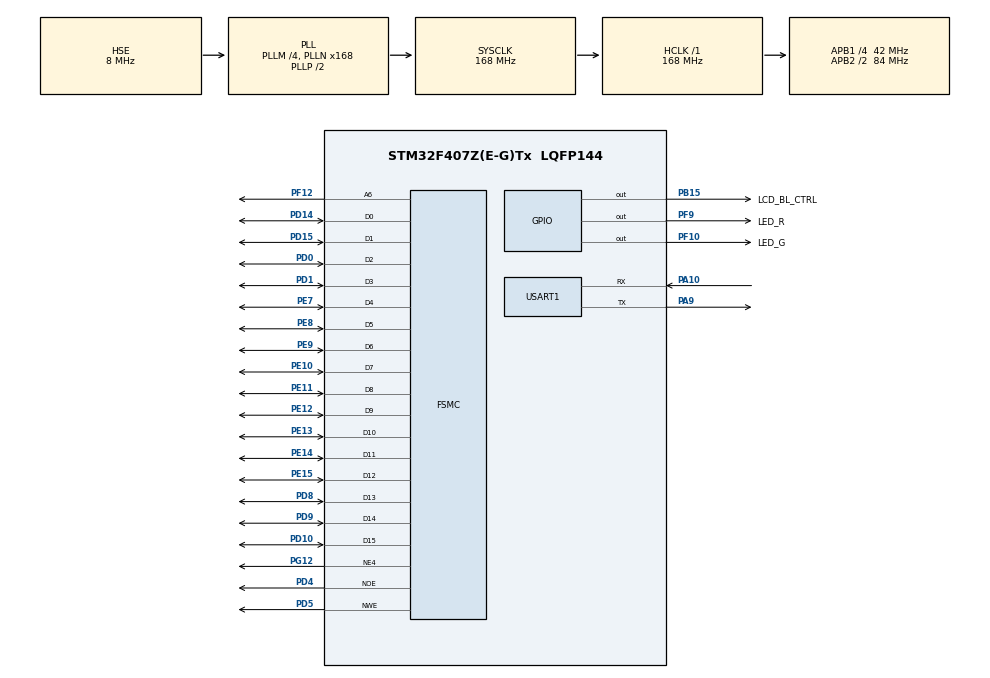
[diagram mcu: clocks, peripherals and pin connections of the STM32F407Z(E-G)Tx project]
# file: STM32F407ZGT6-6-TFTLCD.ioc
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FSMC.BusTurnAroundDuration4=0
FSMC.DataSetupTime4=60
FSMC.ExtendedAddressSetupTime4=3
FSMC.ExtendedBusTurnAroundDuration4=0
FSMC.ExtendedDataSetupTime4=2
FSMC.ExtendedMode4=FSMC_EXTENDED_MODE_ENABLE
Mcu.Family=STM32F4
Mcu.Name=STM32F407Z(E-G)Tx
Mcu.Package=LQFP144
NVIC.PriorityGroup=NVIC_PRIORITYGROUP_2
NVIC.USART1_IRQn=true\:2\:2\:true\:false\:true\:true\:true
PA10.GPIO_PuPd=GPIO_PULLUP
PA10.GPIO_Speed=GPIO_SPEED_FREQ_HIGH
PA10.Mode=Asynchronous
PA10.Signal=USART1_RX
PA13.Mode=Serial_Wire
PA13.Signal=SYS_JTMS-SWDIO
PA14.Mode=Serial_Wire
PA14.Signal=SYS_JTCK-SWCLK
PA9.GPIO_PuPd=GPIO_PULLUP
PA9.GPIO_Speed=GPIO_SPEED_FREQ_HIGH
PA9.Mode=Asynchronous
PA9.Signal=USART1_TX
PB15.GPIO_Label=LCD_BL_CTRL
PB15.GPIO_PuPd=GPIO_PULLUP
PB15.GPIO_Speed=GPIO_SPEED_FREQ_LOW
PB15.PinState=GPIO_PIN_RESET
PB15.Signal=GPIO_Output
PD0.GPIO_PuPd=GPIO_PULLUP
PD0.Signal=FSMC_D2_DA2
PD1.GPIO_PuPd=GPIO_PULLUP
PD1.Signal=FSMC_D3_DA3
PD10.GPIO_PuPd=GPIO_PULLUP
PD10.Signal=FSMC_D15_DA15
PD14.GPIO_PuPd=GPIO_PULLUP
PD14.Signal=FSMC_D0_DA0
PD15.GPIO_PuPd=GPIO_PULLUP
PD15.Signal=FSMC_D1_DA1
PD4.GPIO_PuPd=GPIO_PULLUP
PD4.Signal=FSMC_NOE
PD5.GPIO_PuPd=GPIO_PULLUP
PD5.Signal=FSMC_NWE
PD8.GPIO_PuPd=GPIO_PULLUP
PD8.Signal=FSMC_D13_DA13
PD9.GPIO_PuPd=GPIO_PULLUP
PD9.Signal=FSMC_D14_DA14
PE10.GPIO_PuPd=GPIO_PULLUP
PE10.Signal=FSMC_D7_DA7
PE11.GPIO_PuPd=GPIO_PULLUP
PE11.Signal=FSMC_D8_DA8
PE12.GPIO_PuPd=GPIO_PULLUP
PE12.Signal=FSMC_D9_DA9
PE13.GPIO_PuPd=GPIO_PULLUP
PE13.Signal=FSMC_D10_DA10
PE14.GPIO_PuPd=GPIO_PULLUP
PE14.Signal=FSMC_D11_DA11
PE15.GPIO_PuPd=GPIO_PULLUP
PE15.Signal=FSMC_D12_DA12
PE7.GPIO_PuPd=GPIO_PULLUP
PE7.Signal=FSMC_D4_DA4
PE8.GPIO_PuPd=GPIO_PULLUP
PE8.Signal=FSMC_D5_DA5
PE9.GPIO_PuPd=GPIO_PULLUP
PE9.Signal=FSMC_D6_DA6
PF10.GPIO_Label=LED_G
PF10.GPIO_PuPd=GPIO_PULLUP
PF10.PinState=GPIO_PIN_SET
PF10.Signal=GPIO_Output
PF12.GPIO_PuPd=GPIO_PULLUP
PF12.Signal=FSMC_A6
PF9.GPIO_Label=LED_R
PF9.GPIO_PuPd=GPIO_PULLUP
PF9.PinState=GPIO_PIN_SET
PF9.Signal=GPIO_Output
PG12.GPIO_PuPd=GPIO_PULLUP
PG12.Mode=NorPsramChipSelect4_4
PG12.Signal=FSMC_NE4
PH0-OSC_IN.Mode=HSE-External-Oscillator
PH0-OSC_IN.Signal=RCC_OSC_IN
PH1-OSC_OUT.Mode=HSE-External-Oscillator
PH1-OSC_OUT.Signal=RCC_OSC_OUT
ProjectManager.HeapSize=0x200
ProjectManager.StackSize=0x400
ProjectManager.TargetToolchain=STM32CubeIDE
RCC.48MHZClocksFreq_Value=84000000
RCC.AHBFreq_Value=168000000
RCC.APB1CLKDivider=RCC_HCLK_DIV4
RCC.APB1Freq_Value=42000000
RCC.APB1TimFreq_Value=84000000
RCC.APB2CLKDivider=RCC_HCLK_DIV2
RCC.APB2Freq_Value=84000000
RCC.APB2TimFreq_Value=168000000
RCC.CortexFreq_Value=168000000
RCC.HCLKFreq_Value=168000000
RCC.HSE_VALUE=8000000
RCC.HSI_VALUE=16000000
RCC.LSE_VALUE=32768
RCC.PLLM=4
RCC.PLLN=168
RCC.PLLSourceVirtual=RCC_PLLSOURCE_HSE
RCC.SYSCLKFreq_VALUE=168000000
RCC.SYSCLKSource=RCC_SYSCLKSOURCE_PLLCLK
RCC.VCOOutputFreq_Value=336000000
SH.FSMC_A6.0=FSMC_A6,A6_4
SH.FSMC_D0_DA0.0=FSMC_D0,16b-d4
SH.FSMC_D10_DA10.0=FSMC_D10,16b-d4
SH.FSMC_D11_DA11.0=FSMC_D11,16b-d4
SH.FSMC_D12_DA12.0=FSMC_D12,16b-d4
SH.FSMC_D13_DA13.0=FSMC_D13,16b-d4
SH.FSMC_D14_DA14.0=FSMC_D14,16b-d4
SH.FSMC_D15_DA15.0=FSMC_D15,16b-d4
SH.FSMC_D1_DA1.0=FSMC_D1,16b-d4
SH.FSMC_D2_DA2.0=FSMC_D2,16b-d4
SH.FSMC_D3_DA3.0=FSMC_D3,16b-d4
SH.FSMC_D4_DA4.0=FSMC_D4,16b-d4
SH.FSMC_D5_DA5.0=FSMC_D5,16b-d4
SH.FSMC_D6_DA6.0=FSMC_D6,16b-d4
SH.FSMC_D7_DA7.0=FSMC_D7,16b-d4
SH.FSMC_D8_DA8.0=FSMC_D8,16b-d4
SH.FSMC_D9_DA9.0=FSMC_D9,16b-d4
SH.FSMC_NOE.0=FSMC_NOE,Lcd4
SH.FSMC_NWE.0=FSMC_NWE,Lcd4
USART1.VirtualMode=VM_ASYNC
board=custom

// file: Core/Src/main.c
/* USER CODE BEGIN Header */
/**
  ******************************************************************************
  * @file           : main.c
  * @brief          : Main program body
  ******************************************************************************
  * @attention
  *
  * <h2><center>&copy; Copyright (c) 2021 STMicroelectronics.
  * All rights reserved.</center></h2>
  *
  * This software component is licensed by ST under BSD 3-Clause license,
  * the "License"; You may not use this file except in compliance with the
  * License. You may obtain a copy of the License at:
  *                        opensource.org/licenses/BSD-3-Clause
  *
  ******************************************************************************
  */
/* USER CODE END Header */
#include "main.h"

/* USER CODE BEGIN Includes */
#include "LCD_Def.h"
#include "LCD_API.h"
/* USER CODE END Includes */

UART_HandleTypeDef huart1;

SRAM_HandleTypeDef hsram4;

void SystemClock_Config(void);
static void MX_GPIO_Init(void);
static void MX_FSMC_Init(void);
static void MX_USART1_UART_Init(void);

int main(void)
{

  /* MCU Configuration--------------------------------------------------------*/

  /* Reset of all peripherals, Initializes the Flash interface and the Systick. */
  HAL_Init();

  /* Configure the system clock */
  SystemClock_Config();

  /* Initialize all configured peripherals */
  MX_GPIO_Init();
  MX_FSMC_Init();
  MX_USART1_UART_Init();
  /* USER CODE BEGIN 2 */
  LCD_Init();

  /* USER CODE END 2 */

  /* Infinite loop */
  /* USER CODE BEGIN WHILE */
  int loopIdx = 0;
  while (1)
  {
    /* USER CODE END WHILE */
    switch(loopIdx)
    {
    case 0:
    	LCD_ClearScreen(COLOR_WHITE);
    	break;
    case 1:
    	LCD_ClearScreen(COLOR_BLACK);
    	break;
    case 2:
    	LCD_ClearScreen(COLOR_RED);
    	break;
    case 3:
    	LCD_ClearScreen(COLOR_GREEN);
    	break;
    case 4:
    	LCD_ClearScreen(COLOR_BLUE);
    	break;
    case 5:
    	LCD_ClearScreen(COLOR_MAGENTA);
    	break;
    case 6:
    	LCD_ClearScreen(COLOR_CYAN);
    	break;
    case 7:
    	LCD_ClearScreen(COLOR_GRAY);
    	break;
    case 8:
    	LCD_ClearScreen(COLOR_LGRAY);
    	break;

    default:
    	LCD_ClearScreen(COLOR_WHITE);
    	break;
    }
    loopIdx++;
    if (loopIdx >= 8)
    	loopIdx = 0;

    HAL_GPIO_TogglePin(LED_R_GPIO_Port, LED_R_Pin);
    HAL_GPIO_TogglePin(LED_G_GPIO_Port, LED_G_Pin);

    HAL_Delay(1000);

  }
}

void SystemClock_Config(void)
{
  RCC_OscInitTypeDef RCC_OscInitStruct = {0};
  RCC_ClkInitTypeDef RCC_ClkInitStruct = {0};

  /** Configure the main internal regulator output voltage
  */
  __HAL_RCC_PWR_CLK_ENABLE();
  __HAL_PWR_VOLTAGESCALING_CONFIG(PWR_REGULATOR_VOLTAGE_SCALE1);
  /** Initializes the RCC Oscillators according to the specified parameters
  * in the RCC_OscInitTypeDef structure.
  */
  RCC_OscInitStruct.OscillatorType = RCC_OSCILLATORTYPE_HSE;
  RCC_OscInitStruct.HSEState = RCC_HSE_ON;
  RCC_OscInitStruct.PLL.PLLState = RCC_PLL_ON;
  RCC_OscInitStruct.PLL.PLLSource = RCC_PLLSOURCE_HSE;
  RCC_OscInitStruct.PLL.PLLM = 4;
  RCC_OscInitStruct.PLL.PLLN = 168;
  RCC_OscInitStruct.PLL.PLLP = RCC_PLLP_DIV2;
  RCC_OscInitStruct.PLL.PLLQ = 4;
  if (HAL_RCC_OscConfig(&RCC_OscInitStruct) != HAL_OK)
  {
    Error_Handler();
  }
  /** Initializes the CPU, AHB and APB buses clocks
  */
  RCC_ClkInitStruct.ClockType = RCC_CLOCKTYPE_HCLK|RCC_CLOCKTYPE_SYSCLK
                              |RCC_CLOCKTYPE_PCLK1|RCC_CLOCKTYPE_PCLK2;
  RCC_ClkInitStruct.SYSCLKSource = RCC_SYSCLKSOURCE_PLLCLK;
  RCC_ClkInitStruct.AHBCLKDivider = RCC_SYSCLK_DIV1;
  RCC_ClkInitStruct.APB1CLKDivider = RCC_HCLK_DIV4;
  RCC_ClkInitStruct.APB2CLKDivider = RCC_HCLK_DIV2;

  if (HAL_RCC_ClockConfig(&RCC_ClkInitStruct, FLASH_LATENCY_5) != HAL_OK)
  {
    Error_Handler();
  }
}

static void MX_USART1_UART_Init(void)
{

  huart1.Instance = USART1;
  huart1.Init.BaudRate = 115200;
  huart1.Init.WordLength = UART_WORDLENGTH_8B;
  huart1.Init.StopBits = UART_STOPBITS_1;
  huart1.Init.Parity = UART_PARITY_NONE;
  huart1.Init.Mode = UART_MODE_TX_RX;
  huart1.Init.HwFlowCtl = UART_HWCONTROL_NONE;
  huart1.Init.OverSampling = UART_OVERSAMPLING_16;
  if (HAL_UART_Init(&huart1) != HAL_OK)
  {
    Error_Handler();
  }

}

static void MX_GPIO_Init(void)
{
  GPIO_InitTypeDef GPIO_InitStruct = {0};

  /* GPIO Ports Clock Enable */
  __HAL_RCC_GPIOF_CLK_ENABLE();
  __HAL_RCC_GPIOH_CLK_ENABLE();
  __HAL_RCC_GPIOE_CLK_ENABLE();
  __HAL_RCC_GPIOB_CLK_ENABLE();
  __HAL_RCC_GPIOD_CLK_ENABLE();
  __HAL_RCC_GPIOA_CLK_ENABLE();
  __HAL_RCC_GPIOG_CLK_ENABLE();

  /*Configure GPIO pin Output Level */
  HAL_GPIO_WritePin(GPIOF, LED_R_Pin|LED_G_Pin, GPIO_PIN_SET);

  /*Configure GPIO pin Output Level */
  HAL_GPIO_WritePin(LCD_BL_CTRL_GPIO_Port, LCD_BL_CTRL_Pin, GPIO_PIN_RESET);

  /*Configure GPIO pins : LED_R_Pin LED_G_Pin */
  GPIO_InitStruct.Pin = LED_R_Pin|LED_G_Pin;
  GPIO_InitStruct.Mode = GPIO_MODE_OUTPUT_PP;
  GPIO_InitStruct.Pull = GPIO_PULLUP;
  GPIO_InitStruct.Speed = GPIO_SPEED_FREQ_LOW;
  HAL_GPIO_Init(GPIOF, &GPIO_InitStruct);

  /*Configure GPIO pin : LCD_BL_CTRL_Pin */
  GPIO_InitStruct.Pin = LCD_BL_CTRL_Pin;
  GPIO_InitStruct.Mode = GPIO_MODE_OUTPUT_PP;
  GPIO_InitStruct.Pull = GPIO_PULLUP;
  GPIO_InitStruct.Speed = GPIO_SPEED_FREQ_LOW;
  HAL_GPIO_Init(LCD_BL_CTRL_GPIO_Port, &GPIO_InitStruct);

}

/* FSMC initialization function */
static void MX_FSMC_Init(void)
{

  FSMC_NORSRAM_TimingTypeDef Timing = {0};
  FSMC_NORSRAM_TimingTypeDef ExtTiming = {0};

  /* USER CODE BEGIN FSMC_Init 1 */
  /***********************************************************************
   * AddressHoldTime, BusTurnAroundDuration, CLKDivision, and DataLatency
   * are ignored in asynchronous mode A.
   ***********************************************************************/
  /* USER CODE END FSMC_Init 1 */

  /** Perform the SRAM4 memory initialization sequence
  */
  hsram4.Instance = FSMC_NORSRAM_DEVICE;
  hsram4.Extended = FSMC_NORSRAM_EXTENDED_DEVICE;
  /* hsram4.Init */
  hsram4.Init.NSBank = FSMC_NORSRAM_BANK4;
  hsram4.Init.DataAddressMux = FSMC_DATA_ADDRESS_MUX_DISABLE;
  hsram4.Init.MemoryType = FSMC_MEMORY_TYPE_SRAM;
  hsram4.Init.MemoryDataWidth = FSMC_NORSRAM_MEM_BUS_WIDTH_16;
  hsram4.Init.BurstAccessMode = FSMC_BURST_ACCESS_MODE_DISABLE;
  hsram4.Init.WaitSignalPolarity = FSMC_WAIT_SIGNAL_POLARITY_LOW;
  hsram4.Init.WrapMode = FSMC_WRAP_MODE_DISABLE;
  hsram4.Init.WaitSignalActive = FSMC_WAIT_TIMING_BEFORE_WS;
  hsram4.Init.WriteOperation = FSMC_WRITE_OPERATION_ENABLE;
  hsram4.Init.WaitSignal = FSMC_WAIT_SIGNAL_DISABLE;
  hsram4.Init.ExtendedMode = FSMC_EXTENDED_MODE_ENABLE;
  hsram4.Init.AsynchronousWait = FSMC_ASYNCHRONOUS_WAIT_DISABLE;
  hsram4.Init.WriteBurst = FSMC_WRITE_BURST_DISABLE;
  hsram4.Init.PageSize = FSMC_PAGE_SIZE_NONE;
  /* Timing */
  Timing.AddressSetupTime = 15;
  Timing.AddressHoldTime = 15;
  Timing.DataSetupTime = 10;
  Timing.BusTurnAroundDuration = 0;
  Timing.CLKDivision = 16;
  Timing.DataLatency = 17;
  Timing.AccessMode = FSMC_ACCESS_MODE_A;
  /* ExtTiming */
  ExtTiming.AddressSetupTime = 3;
  ExtTiming.AddressHoldTime = 15;
  ExtTiming.DataSetupTime = 2;
  ExtTiming.BusTurnAroundDuration = 0;
  ExtTiming.CLKDivision = 16;
  ExtTiming.DataLatency = 17;
  ExtTiming.AccessMode = FSMC_ACCESS_MODE_A;

  if (HAL_SRAM_Init(&hsram4, &Timing, &ExtTiming) != HAL_OK)
  {
    Error_Handler( );
  }

}

void Error_Handler(void)
{
  __disable_irq();
  while (1)
  {
  }
}

/************************ (C) COPYRIGHT STMicroelectronics *****END OF FILE****/
